VERSION "1.1.0"

NS_ :

BS_:

BU_: Tester RearECU MyECU

BO_ 3221225472 VECTOR__INDEPENDENT_SIG_MSG: 0 Vector__XXX
 SG_ sig_nm_RearECU : 0|64@1+ (1,0) [0|1.8446744074E+019] "" Vector__XXX
 SG_ sig_nm_MyECU : 0|64@1+ (1,0) [0|1.8446744074E+019] "" Vector__XXX
 SG_ sig_NM_MyECU_NID : 0|8@1+ (1,0) [0|255] "" Vector__XXX
 SG_ sig_NM_MyECU_CBV : 0|8@1+ (1,0) [0|255] "" Vector__XXX
 SG_ sig_NM_MyECU_UserData_0 : 0|8@1+ (1,0) [0|255] "" Vector__XXX
 SG_ sig_NM_MyECU_UserData_1 : 0|8@1+ (1,0) [0|255] "" Vector__XXX
 SG_ sig_NM_MyECU_UserData_2 : 0|8@1+ (1,0) [0|255] "" Vector__XXX
 SG_ sig_NM_MyECU_UserData_3 : 0|8@1+ (1,0) [0|255] "" Vector__XXX
 SG_ sig_NM_MyECU_UserData_4 : 0|8@1+ (1,0) [0|255] "" Vector__XXX
 SG_ sig_NM_MyECU_UserData_5 : 0|8@1+ (1,0) [0|255] "" Vector__XXX
 SG_ sig_NM_RearECU_NID : 0|8@1+ (1,0) [0|255] "" Vector__XXX
 SG_ sig_NM_RearECU_CBV : 0|8@1+ (1,0) [0|255] "" Vector__XXX
 SG_ sig_NM_RearECU_UserData_0 : 0|8@1+ (1,0) [0|255] "" Vector__XXX
 SG_ sig_NM_RearECU_UserData_1 : 0|8@1+ (1,0) [0|255] "" Vector__XXX
 SG_ sig_NM_RearECU_UserData_2 : 0|8@1+ (1,0) [0|255] "" Vector__XXX
 SG_ sig_NM_RearECU_UserData_3 : 0|8@1+ (1,0) [0|255] "" Vector__XXX
 SG_ sig_NM_RearECU_UserData_4 : 0|8@1+ (1,0) [0|255] "" Vector__XXX
 SG_ sig_NM_RearECU_UserData_5 : 0|8@1+ (1,0) [0|255] "" Vector__XXX

BO_ 1297 msg_MotorStatus: 12 MyECU
 SG_ MotorMode : 0|8@1+ (1,0) [0|7] ""  Tester
 SG_ tle9180_Ov_Fault : 8|1@1+ (1,0) [0|1] ""  Tester
 SG_ Id_Ref : 16|16@1- (0.01,0) [-327.68|327.67] "A"  Tester
 SG_ Iq_Ref : 32|16@1- (0.01,0) [-327.68|327.67] "A"  Tester
 SG_ Vbus : 48|16@1- (0.1,0) [-3276.8|3276.7] "V"  Tester
 SG_ ElectricAngle : 64|16@1- (0.001,0) [-32.768|32.767] "rad"  Tester

BO_ 512 msg_Transmit: 1 MyECU
 SG_ sig_RearInteriorLight : 0|1@1+ (1,0) [0|1] ""  RearECU

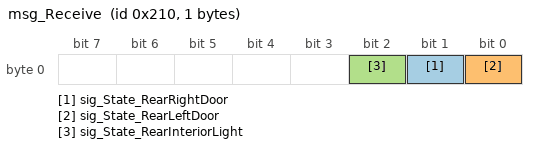
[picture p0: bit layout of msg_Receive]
BO_ 528 msg_Receive: 1 RearECU
 SG_ sig_State_RearRightDoor : 1|1@1+ (1,0) [0|1] ""  MyECU
 SG_ sig_State_RearLeftDoor : 0|1@1+ (1,0) [0|1] ""  MyECU
 SG_ sig_State_RearInteriorLight : 2|1@1+ (1,0) [0|1] ""  MyECU

BO_ 1868 msg_diag_Request_MyECU: 8 Tester
 SG_ Signal_DiagRequestMyECU : 0|64@1+ (1,0) [0|1.8446744074E+019] ""  MyECU

BO_ 1884 msg_diag_Response_MyECU: 8 MyECU
 SG_ Signal_DiagResponseMyECU : 0|64@1+ (1,0) [0|1.8446744074E+019] ""  Tester

BO_ 2015 msg_diag_RequestGlobal: 8 Tester
 SG_ Signal_DiagRequestGlobal : 0|64@1+ (1,0) [0|1.8446744074E+019] ""  MyECU

CM_ "AUTOSAR series communication matrix (application + NM + UDS diag 0x74C/0x75C/0x7DF). Calibration/XCP is NOT part of this matrix; see CANFD364_XCP_Dev.dbc and configure Xcp PDU in DaVinci/EcuC only.";
CM_ BO_ 3221225472 "This is a message for not used signals, created by Vector CANdb++ DBC OLE DB Provider.";
CM_ BO_ 1297 "MyECU TX motor status (Com). Cycle 5 ms, CAN FD. Signals align with RTE: MotorMode, tle9180_Ov_Fault, Id_Ref, Iq_Ref, Vbus, ElectricAngle. Observation only; mode/current commands via XCP RAM write, not Com Rx.";
CM_ BO_ 512 "Legacy demo TX frame (kept for existing CanIf/Com). Prefer remove in later series cleanup if unused.";
CM_ BO_ 528 "Legacy demo RX frame (kept for existing CanIf/Com). Prefer remove in later series cleanup if unused.";
CM_ BO_ 1868 "UDS physical request (ID 0x74C, Tester -> MyECU), 8 bytes classic CAN. Dcm Rx PDU (physical addressing).";
CM_ BO_ 1884 "UDS physical response (ID 0x75C, MyECU -> Tester), 8 bytes classic CAN. Dcm Tx PDU.";
CM_ BO_ 2015 "UDS functional request (ID 0x7DF, broadcast), 8 bytes classic CAN. Dcm Rx PDU (functional addressing).";
CM_ SG_ 1297 MotorMode "Aligned with MotorMode_Type in MotorMode.h (0..7).";
CM_ SG_ 1297 Id_Ref "Actual Id current reference after clamp [A].";
CM_ SG_ 1297 Iq_Ref "Actual Iq current reference after clamp [A].";

BA_DEF_ BO_  "VFrameFormat" ENUM  "StandardCAN","ExtendedCAN","reserved","reserved","reserved","reserved","reserved","reserved","reserved","reserved","reserved","reserved","reserved","reserved","StandardCAN_FD","ExtendedCAN_FD";
BA_DEF_ BO_  "GenMsgCycleTime" INT 0 100000;
BA_DEF_ BO_  "GenMsgSendType" ENUM  "cyclicX","spontanX","cyclicIfActiveX","spontanWithDelay","cyclicAndSpontanX","cyclicAndSpontanWithDelay","spontanWithRepetition","cyclicIfActiveAndSpontanWD","cyclicIfActiveFast","cyclicWithRepeatOnDemand";
BA_DEF_ SG_  "GenSigCycleTimeActive" INT 0 0;
BA_DEF_ SG_  "GenSigCycleTime" INT 0 0;
BA_DEF_ SG_  "GenSigSendType" ENUM  "cyclicX","spontanX","cyclicIfActiveX","spontanWithDelay","cyclicAndSpontanX","cyclicAndSpontanWithDelay","spontanWithRepetition","cyclicIfActiveAndSpontanWD","cyclicIfActiveFast","cyclicWithRepeatOnDemand","none","NotUsed","NotUsed";
BA_DEF_  "Baudrate" INT 0 1000000;
BA_DEF_  "BusType" STRING ;
BA_DEF_  "Manufacturer" STRING ;
BA_DEF_  "DbName" STRING ;
BA_DEF_  "ProtocolType" STRING ;
BA_DEF_ BU_  "ILUsed" ENUM  "No","Yes";
BA_DEF_ BO_  "GenMsgILSupport" ENUM  "No","Yes";
BA_DEF_ BO_  "DiagConnection" INT 0 65535;
BA_DEF_ BO_  "DiagRequest" ENUM  "No","Yes";
BA_DEF_ BO_  "DiagResponse" ENUM  "No","Yes";
BA_DEF_DEF_  "VFrameFormat" "StandardCAN_FD";
BA_DEF_DEF_  "GenMsgCycleTime" 0;
BA_DEF_DEF_  "GenMsgSendType" "cyclicX";
BA_DEF_DEF_  "GenSigCycleTimeActive" 0;
BA_DEF_DEF_  "GenSigCycleTime" 0;
BA_DEF_DEF_  "GenSigSendType" "cyclicX";
BA_DEF_DEF_  "Baudrate" 500000;
BA_DEF_DEF_  "BusType" "CAN FD";
BA_DEF_DEF_  "Manufacturer" "CLBT";
BA_DEF_DEF_  "DbName" "CANFD364";
BA_DEF_DEF_  "ProtocolType" "StandardCAN";
BA_DEF_DEF_  "ILUsed" "Yes";
BA_DEF_DEF_  "GenMsgILSupport" "Yes";
BA_DEF_DEF_  "DiagConnection" 0;
BA_DEF_DEF_  "DiagRequest" "No";
BA_DEF_DEF_  "DiagResponse" "No";

BA_ "GenMsgCycleTime" BO_ 1297 5;

BA_ "VFrameFormat" BO_ 512 0;
BA_ "GenMsgCycleTime" BO_ 512 100;

BA_ "VFrameFormat" BO_ 528 0;
BA_ "GenMsgCycleTime" BO_ 528 100;

BA_ "VFrameFormat" BO_ 1868 0;
BA_ "GenMsgSendType" BO_ 1868 1;
BA_ "DiagConnection" BO_ 1868 57345;
BA_ "DiagRequest" BO_ 1868 1;

BA_ "VFrameFormat" BO_ 1884 0;
BA_ "GenMsgSendType" BO_ 1884 1;
BA_ "DiagConnection" BO_ 1884 57345;
BA_ "DiagResponse" BO_ 1884 1;

BA_ "VFrameFormat" BO_ 2015 0;
BA_ "GenMsgSendType" BO_ 2015 1;
BA_ "DiagConnection" BO_ 2015 57345;
BA_ "DiagRequest" BO_ 2015 1;

BA_ "GenSigCycleTime" SG_ 3221225472 sig_nm_RearECU 100;
BA_ "GenSigCycleTimeActive" SG_ 3221225472 sig_nm_RearECU 100;
BA_ "GenSigCycleTime" SG_ 3221225472 sig_nm_MyECU 100;
BA_ "GenSigCycleTimeActive" SG_ 3221225472 sig_nm_MyECU 100;
BA_ "GenSigCycleTime" SG_ 3221225472 sig_NM_MyECU_NID 100;
BA_ "GenSigCycleTimeActive" SG_ 3221225472 sig_NM_MyECU_NID 100;
BA_ "GenSigCycleTime" SG_ 3221225472 sig_NM_MyECU_CBV 100;
BA_ "GenSigCycleTimeActive" SG_ 3221225472 sig_NM_MyECU_CBV 100;
BA_ "GenSigCycleTime" SG_ 3221225472 sig_NM_MyECU_UserData_0 100;
BA_ "GenSigCycleTimeActive" SG_ 3221225472 sig_NM_MyECU_UserData_0 100;
BA_ "GenSigCycleTime" SG_ 3221225472 sig_NM_MyECU_UserData_1 100;
BA_ "GenSigCycleTimeActive" SG_ 3221225472 sig_NM_MyECU_UserData_1 100;
BA_ "GenSigCycleTime" SG_ 3221225472 sig_NM_MyECU_UserData_2 100;
BA_ "GenSigCycleTimeActive" SG_ 3221225472 sig_NM_MyECU_UserData_2 100;
BA_ "GenSigCycleTime" SG_ 3221225472 sig_NM_MyECU_UserData_3 100;
BA_ "GenSigCycleTimeActive" SG_ 3221225472 sig_NM_MyECU_UserData_3 100;
BA_ "GenSigCycleTime" SG_ 3221225472 sig_NM_MyECU_UserData_4 100;
BA_ "GenSigCycleTimeActive" SG_ 3221225472 sig_NM_MyECU_UserData_4 100;
BA_ "GenSigCycleTime" SG_ 3221225472 sig_NM_MyECU_UserData_5 100;
BA_ "GenSigCycleTimeActive" SG_ 3221225472 sig_NM_MyECU_UserData_5 100;
BA_ "GenSigCycleTime" SG_ 3221225472 sig_NM_RearECU_NID 100;
BA_ "GenSigCycleTimeActive" SG_ 3221225472 sig_NM_RearECU_NID 100;
BA_ "GenSigCycleTime" SG_ 3221225472 sig_NM_RearECU_CBV 100;
BA_ "GenSigCycleTimeActive" SG_ 3221225472 sig_NM_RearECU_CBV 100;
BA_ "GenSigCycleTime" SG_ 3221225472 sig_NM_RearECU_UserData_0 100;
BA_ "GenSigCycleTimeActive" SG_ 3221225472 sig_NM_RearECU_UserData_0 100;
BA_ "GenSigCycleTime" SG_ 3221225472 sig_NM_RearECU_UserData_1 100;
BA_ "GenSigCycleTimeActive" SG_ 3221225472 sig_NM_RearECU_UserData_1 100;
BA_ "GenSigCycleTime" SG_ 3221225472 sig_NM_RearECU_UserData_2 100;
BA_ "GenSigCycleTimeActive" SG_ 3221225472 sig_NM_RearECU_UserData_2 100;
BA_ "GenSigCycleTime" SG_ 3221225472 sig_NM_RearECU_UserData_3 100;
BA_ "GenSigCycleTimeActive" SG_ 3221225472 sig_NM_RearECU_UserData_3 100;
BA_ "GenSigCycleTime" SG_ 3221225472 sig_NM_RearECU_UserData_4 100;
BA_ "GenSigCycleTimeActive" SG_ 3221225472 sig_NM_RearECU_UserData_4 100;
BA_ "GenSigCycleTime" SG_ 3221225472 sig_NM_RearECU_UserData_5 100;
BA_ "GenSigCycleTimeActive" SG_ 3221225472 sig_NM_RearECU_UserData_5 100;
BA_ "GenSigCycleTime" SG_ 512 sig_RearInteriorLight 100;
BA_ "GenSigCycleTimeActive" SG_ 512 sig_RearInteriorLight 100;
BA_ "GenSigCycleTime" SG_ 528 sig_State_RearRightDoor 100;
BA_ "GenSigCycleTimeActive" SG_ 528 sig_State_RearRightDoor 100;
BA_ "GenSigCycleTime" SG_ 528 sig_State_RearLeftDoor 100;
BA_ "GenSigCycleTimeActive" SG_ 528 sig_State_RearLeftDoor 100;
BA_ "GenSigCycleTime" SG_ 528 sig_State_RearInteriorLight 100;
BA_ "GenSigCycleTimeActive" SG_ 528 sig_State_RearInteriorLight 100;

VAL_ 1297 MotorMode 0 "Idle" 1 "Stop" 2 "FocSpeed" 3 "FocCurrent" 4 "OpenLoop" 5 "Calibration" 6 "CalibrationErase" 7 "CalibrationSave";
VAL_ 1297 tle9180_Ov_Fault 0 "NoFault" 1 "OverVoltageFault";
